# CY8C5287AXI_LP095 register map
File version: 0.1
CY8C52LP
Registers are 8-bit, read-write, no defined reset value unless marked. A register's access mark holds for its fields unless they carry their own. Offsets are from the block's base; lines under a group give offsets from that group; [hi:lo] are bit positions; {n}, {i} and the like mark numbered series; 'fields as' and 'values as' point back to an identical list; <NAME> marks a mode.

## Memory map
0x40004394 USBFS_1 size 0x1D0A — USBFS
0x4000646B DipSwReadReg size 0x31
0x4000647B LEDControl size 0x1

## DipSwReadReg
Base 0x4000646B
0x00 DipSwReadReg_STATUS_REG
0x20 DipSwReadReg_MASK_REG
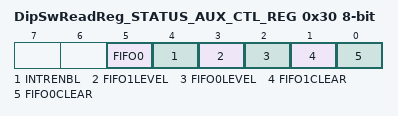
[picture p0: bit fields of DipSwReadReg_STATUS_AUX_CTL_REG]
0x30 DipSwReadReg_STATUS_AUX_CTL_REG
  [5] FIFO0 — FIFO0 clear
    1=ENABLED (Enable counter); 0=DISABLED (Disable counter)
  [4] INTRENBL — Enables or disables the Interrupt
    1=ENABLED (Interrupt enabled); 0=DISABLED (Interrupt disabled)
  [3] FIFO1LEVEL — FIFO level
    1=ENABLED (FIFO LVL: input mode: FIFO at least 1/2 empty; output mode: FIFO at least 1/2 full); 0=DISABLED (FIFO LVL: input mode: FIFO not full; output mode: FIFO not empty)
  [2] FIFO0LEVEL — FIFO level
    values as FIFO1LEVEL
  [1] FIFO1CLEAR — FIFO clear
    1=ENABLED (Clear FIFO state); 0=DISABLED (Normal FIFO operation)
  [0] FIFO0CLEAR — FIFO clear
    values as FIFO1CLEAR

## LEDControl
Base 0x4000647B
0x00 LEDControl_CONTROL_REG

## USBFS_1 — USBFS
Base 0x40004394
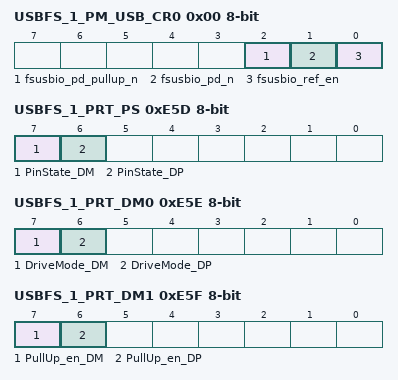
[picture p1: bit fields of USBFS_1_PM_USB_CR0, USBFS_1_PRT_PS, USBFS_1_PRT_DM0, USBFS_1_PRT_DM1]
0x00 USBFS_1_PM_USB_CR0 — USB Power Mode Control Register 0
  [2] fsusbio_pd_pullup_n, [1] fsusbio_pd_n, [0] fsusbio_ref_en
0x11 USBFS_1_PM_ACT_CFG — Active Power Mode Configuration Register
0x21 USBFS_1_PM_STBY_CFG — Standby Power Mode Configuration Register
0xE5D USBFS_1_PRT_PS — Port Pin State Register
  [7] PinState_DM ro, [6] PinState_DP ro
0xE5E USBFS_1_PRT_DM0 — Port Drive Mode Register
  [7] DriveMode_DM, [6] DriveMode_DP
0xE5F USBFS_1_PRT_DM1 — Port Drive Mode Register
  [7] PullUp_en_DM, [6] PullUp_en_DP
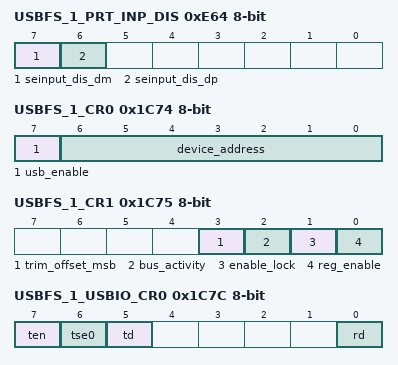
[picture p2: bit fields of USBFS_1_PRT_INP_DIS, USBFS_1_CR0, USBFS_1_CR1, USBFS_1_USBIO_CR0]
0xE64 USBFS_1_PRT_INP_DIS — Input buffer disable override
  [7] seinput_dis_dm, [6] seinput_dis_dp
0x1C6C USBFS_1_EP0_DR0 — bmRequestType
0x1C6D USBFS_1_EP0_DR1 — bRequest
0x1C6E USBFS_1_EP0_DR2 — wValueLo
0x1C6F USBFS_1_EP0_DR3 — wValueHi
0x1C70 USBFS_1_EP0_DR4 — wIndexLo
0x1C71 USBFS_1_EP0_DR5 — wIndexHi
0x1C72 USBFS_1_EP0_DR6 — lengthLo
0x1C73 USBFS_1_EP0_DR7 — lengthHi
0x1C74 USBFS_1_CR0 — USB Control Register 0
  [7] usb_enable, [6:0] device_address ro
0x1C75 USBFS_1_CR1 — USB Control Register 1
  [3] trim_offset_msb, [2] bus_activity, [1] enable_lock, [0] reg_enable
{0x1C6A+0x10*i} USBFS_1_SIE_EP{i}_CR0 (i=1..8) — The Endpoint{i} Control Register
0x1C7C USBFS_1_USBIO_CR0 — USBIO Control Register 0
  [7] ten, [6] tse0, [5] td, [0] rd ro
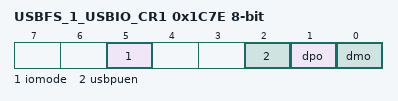
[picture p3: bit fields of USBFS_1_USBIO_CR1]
0x1C7E USBFS_1_USBIO_CR1 — USBIO Control Register 1
  [5] iomode, [2] usbpuen, [1] dpo ro, [0] dmo ro
0x1CF8 USBFS_1_BUF_SIZE — Dedicated Endpoint Buffer Size Register
0x1CFA USBFS_1_EP_ACTIVE — Endpoint Active Indication Register
0x1CFB USBFS_1_EP_TYPE — Endpoint Type (IN/OUT) Indication
0x1D09 USBFS_1_USB_CLK_EN — USB Block Clock Enable Register
